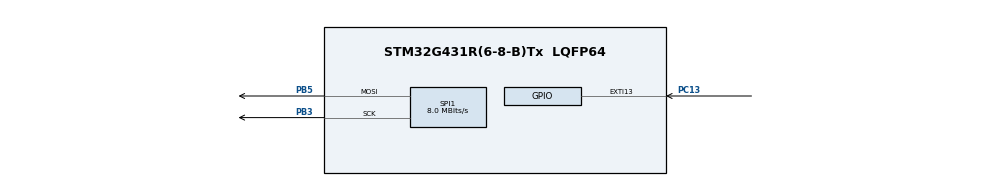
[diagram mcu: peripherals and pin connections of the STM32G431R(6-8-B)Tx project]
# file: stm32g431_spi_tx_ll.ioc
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Dma.Request0=SPI1_TX
Dma.SPI1_TX.0.Direction=DMA_MEMORY_TO_PERIPH
Dma.SPI1_TX.0.EventEnable=DISABLE
Dma.SPI1_TX.0.Instance=DMA1_Channel2
Dma.SPI1_TX.0.MemDataAlignment=DMA_MDATAALIGN_HALFWORD
Dma.SPI1_TX.0.MemInc=DMA_MINC_ENABLE
Dma.SPI1_TX.0.Mode=DMA_NORMAL
Dma.SPI1_TX.0.PeriphDataAlignment=DMA_PDATAALIGN_HALFWORD
Dma.SPI1_TX.0.PeriphInc=DMA_PINC_DISABLE
Dma.SPI1_TX.0.Polarity=HAL_DMAMUX_REQ_GEN_RISING
Dma.SPI1_TX.0.Priority=DMA_PRIORITY_LOW
Dma.SPI1_TX.0.RequestNumber=1
Dma.SPI1_TX.0.SignalID=NONE
Dma.SPI1_TX.0.SyncEnable=DISABLE
Dma.SPI1_TX.0.SyncPolarity=HAL_DMAMUX_SYNC_NO_EVENT
Dma.SPI1_TX.0.SyncRequestNumber=1
Dma.SPI1_TX.0.SyncSignalID=NONE
Mcu.Family=STM32G4
Mcu.Name=STM32G431R(6-8-B)Tx
Mcu.Package=LQFP64
NVIC.DMA1_Channel2_IRQn=true\:0\:0\:false\:false\:true\:false\:true\:true
NVIC.EXTI15_10_IRQn=true\:0\:0\:false\:false\:true\:true\:true\:true
NVIC.PriorityGroup=NVIC_PRIORITYGROUP_4
PB3.Mode=TX_Only_Simplex_Unidirect_Master
PB3.Signal=SPI1_SCK
PB5.Mode=TX_Only_Simplex_Unidirect_Master
PB5.Signal=SPI1_MOSI
PC13.Signal=GPXTI13
ProjectManager.HeapSize=0x200
ProjectManager.StackSize=0x400
ProjectManager.TargetToolchain=STM32CubeIDE
RCC.AHBFreq_Value=16000000
RCC.APB1Freq_Value=16000000
RCC.APB1TimFreq_Value=16000000
RCC.APB2Freq_Value=16000000
RCC.APB2TimFreq_Value=16000000
RCC.CortexFreq_Value=16000000
RCC.EXTERNAL_CLOCK_VALUE=12288000
RCC.HCLKFreq_Value=16000000
RCC.HSE_VALUE=8000000
RCC.HSI48_VALUE=48000000
RCC.HSI_VALUE=16000000
RCC.LSE_VALUE=32768
RCC.SYSCLKFreq_VALUE=16000000
RCC.USBFreq_Value=64000000
RCC.VCOOutputFreq_Value=128000000
SPI1.CLKPhase=SPI_PHASE_2EDGE
SPI1.CLKPolarity=SPI_POLARITY_HIGH
SPI1.CalculateBaudRate=8.0 MBits/s
SPI1.DataSize=SPI_DATASIZE_16BIT
SPI1.Direction=SPI_DIRECTION_2LINES
SPI1.Mode=SPI_MODE_MASTER
SPI1.VirtualType=VM_MASTER
VP_SYS_VS_DBSignals.Mode=DisableDeadBatterySignals
board=custom

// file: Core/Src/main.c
/* USER CODE BEGIN Header */
/**
  ******************************************************************************
  * @file           : main.c
  * @brief          : Main program body
  ******************************************************************************
  * @attention
  *
  * Copyright (c) 2023 STMicroelectronics.
  * All rights reserved.
  *
  * This software is licensed under terms that can be found in the LICENSE file
  * in the root directory of this software component.
  * If no LICENSE file comes with this software, it is provided AS-IS.
  *
  ******************************************************************************
  */
/* USER CODE END Header */
#include "main.h"

void SystemClock_Config(void);
static void MX_GPIO_Init(void);
static void MX_DMA_Init(void);
static void MX_SPI1_Init(void);

/* USER CODE BEGIN 0 */
uint8_t aTxBuffer[] = {0xAA, 0xAA};
uint8_t ubNbDataToTransmit = 1;
/* USER CODE END 0 */

int main(void)
{

  /* MCU Configuration--------------------------------------------------------*/

  /* Reset of all peripherals, Initializes the Flash interface and the Systick. */
  LL_APB2_GRP1_EnableClock(LL_APB2_GRP1_PERIPH_SYSCFG);
  LL_APB1_GRP1_EnableClock(LL_APB1_GRP1_PERIPH_PWR);

  /* System interrupt init*/
  NVIC_SetPriorityGrouping(NVIC_PRIORITYGROUP_4);

  /* SysTick_IRQn interrupt configuration */
  NVIC_SetPriority(SysTick_IRQn, NVIC_EncodePriority(NVIC_GetPriorityGrouping(),15, 0));

  /** Disable the internal Pull-Up in Dead Battery pins of UCPD peripheral
  */
  LL_PWR_DisableUCPDDeadBattery();

  /* Configure the system clock */
  SystemClock_Config();

  /* Initialize all configured peripherals */
  MX_GPIO_Init();
  MX_DMA_Init();
  MX_SPI1_Init();
  /* USER CODE BEGIN 2 */
  LL_SPI_SetRxFIFOThreshold(SPI1, LL_SPI_RX_FIFO_TH_HALF);
  LL_DMA_ConfigAddresses(DMA1,
                         LL_DMA_CHANNEL_2,
                         (uint32_t)aTxBuffer,
                         LL_SPI_DMA_GetRegAddr(SPI1),
                         LL_DMA_GetDataTransferDirection(DMA1, LL_DMA_CHANNEL_2));

  LL_DMA_SetDataLength(DMA1, LL_DMA_CHANNEL_2, ubNbDataToTransmit);
  LL_DMA_SetPeriphRequest(DMA1, LL_DMA_CHANNEL_2, LL_DMAMUX_REQ_SPI1_TX);
  LL_DMA_EnableIT_TC(DMA1, LL_DMA_CHANNEL_2);
  LL_DMA_EnableIT_TE(DMA1, LL_DMA_CHANNEL_2);

  //LL_SPI_EnableIT_TXE(SPI1);
  //LL_DMA_EnableChannel(DMA1, LL_DMA_CHANNEL_2);
  //LL_SPI_EnableDMAReq_TX(SPI1);
  //LL_SPI_Enable(SPI1);

  /* USER CODE END 2 */

  /* Infinite loop */
  while (1)
  {

  }
}

void SystemClock_Config(void)
{
  LL_FLASH_SetLatency(LL_FLASH_LATENCY_0);
  while(LL_FLASH_GetLatency() != LL_FLASH_LATENCY_0)
  {
  }
  LL_PWR_SetRegulVoltageScaling(LL_PWR_REGU_VOLTAGE_SCALE1);
  LL_RCC_HSI_Enable();
   /* Wait till HSI is ready */
  while(LL_RCC_HSI_IsReady() != 1)
  {
  }

  LL_RCC_HSI_SetCalibTrimming(64);
  LL_RCC_SetSysClkSource(LL_RCC_SYS_CLKSOURCE_HSI);
   /* Wait till System clock is ready */
  while(LL_RCC_GetSysClkSource() != LL_RCC_SYS_CLKSOURCE_STATUS_HSI)
  {
  }

  /* Set AHB prescaler*/
  LL_RCC_SetAHBPrescaler(LL_RCC_SYSCLK_DIV_1);
  LL_RCC_SetAPB1Prescaler(LL_RCC_APB1_DIV_1);
  LL_RCC_SetAPB2Prescaler(LL_RCC_APB2_DIV_1);

  LL_Init1msTick(16000000);

  LL_SetSystemCoreClock(16000000);
}

static void MX_SPI1_Init(void)
{

  LL_SPI_InitTypeDef SPI_InitStruct = {0};

  LL_GPIO_InitTypeDef GPIO_InitStruct = {0};

  /* Peripheral clock enable */
  LL_APB2_GRP1_EnableClock(LL_APB2_GRP1_PERIPH_SPI1);

  LL_AHB2_GRP1_EnableClock(LL_AHB2_GRP1_PERIPH_GPIOB);
  /**SPI1 GPIO Configuration
  PB3   ------> SPI1_SCK
  PB5   ------> SPI1_MOSI
  */
  GPIO_InitStruct.Pin = LL_GPIO_PIN_3;
  GPIO_InitStruct.Mode = LL_GPIO_MODE_ALTERNATE;
  GPIO_InitStruct.Speed = LL_GPIO_SPEED_FREQ_LOW;
  GPIO_InitStruct.OutputType = LL_GPIO_OUTPUT_PUSHPULL;
  GPIO_InitStruct.Pull = LL_GPIO_PULL_NO;
  GPIO_InitStruct.Alternate = LL_GPIO_AF_5;
  LL_GPIO_Init(GPIOB, &GPIO_InitStruct);

  GPIO_InitStruct.Pin = LL_GPIO_PIN_5;
  GPIO_InitStruct.Mode = LL_GPIO_MODE_ALTERNATE;
  GPIO_InitStruct.Speed = LL_GPIO_SPEED_FREQ_LOW;
  GPIO_InitStruct.OutputType = LL_GPIO_OUTPUT_PUSHPULL;
  GPIO_InitStruct.Pull = LL_GPIO_PULL_NO;
  GPIO_InitStruct.Alternate = LL_GPIO_AF_5;
  LL_GPIO_Init(GPIOB, &GPIO_InitStruct);

  /* SPI1 DMA Init */

  /* SPI1_TX Init */
  LL_DMA_SetPeriphRequest(DMA1, LL_DMA_CHANNEL_2, LL_DMAMUX_REQ_SPI1_TX);

  LL_DMA_SetDataTransferDirection(DMA1, LL_DMA_CHANNEL_2, LL_DMA_DIRECTION_MEMORY_TO_PERIPH);

  LL_DMA_SetChannelPriorityLevel(DMA1, LL_DMA_CHANNEL_2, LL_DMA_PRIORITY_LOW);

  LL_DMA_SetMode(DMA1, LL_DMA_CHANNEL_2, LL_DMA_MODE_NORMAL);

  LL_DMA_SetPeriphIncMode(DMA1, LL_DMA_CHANNEL_2, LL_DMA_PERIPH_NOINCREMENT);

  LL_DMA_SetMemoryIncMode(DMA1, LL_DMA_CHANNEL_2, LL_DMA_MEMORY_INCREMENT);

  LL_DMA_SetPeriphSize(DMA1, LL_DMA_CHANNEL_2, LL_DMA_PDATAALIGN_HALFWORD);

  LL_DMA_SetMemorySize(DMA1, LL_DMA_CHANNEL_2, LL_DMA_MDATAALIGN_HALFWORD);

  /* SPI1 parameter configuration*/
  SPI_InitStruct.TransferDirection = LL_SPI_FULL_DUPLEX;
  SPI_InitStruct.Mode = LL_SPI_MODE_MASTER;
  SPI_InitStruct.DataWidth = LL_SPI_DATAWIDTH_16BIT;
  SPI_InitStruct.ClockPolarity = LL_SPI_POLARITY_HIGH;
  SPI_InitStruct.ClockPhase = LL_SPI_PHASE_2EDGE;
  SPI_InitStruct.NSS = LL_SPI_NSS_SOFT;
  SPI_InitStruct.BaudRate = LL_SPI_BAUDRATEPRESCALER_DIV2;
  SPI_InitStruct.BitOrder = LL_SPI_MSB_FIRST;
  SPI_InitStruct.CRCCalculation = LL_SPI_CRCCALCULATION_DISABLE;
  SPI_InitStruct.CRCPoly = 7;
  LL_SPI_Init(SPI1, &SPI_InitStruct);
  LL_SPI_SetStandard(SPI1, LL_SPI_PROTOCOL_MOTOROLA);
  LL_SPI_DisableNSSPulseMgt(SPI1);

}

static void MX_DMA_Init(void)
{

  /* Init with LL driver */
  /* DMA controller clock enable */
  LL_AHB1_GRP1_EnableClock(LL_AHB1_GRP1_PERIPH_DMAMUX1);
  LL_AHB1_GRP1_EnableClock(LL_AHB1_GRP1_PERIPH_DMA1);

  /* DMA interrupt init */
  /* DMA1_Channel2_IRQn interrupt configuration */
  NVIC_SetPriority(DMA1_Channel2_IRQn, NVIC_EncodePriority(NVIC_GetPriorityGrouping(),0, 0));
  NVIC_EnableIRQ(DMA1_Channel2_IRQn);

}

static void MX_GPIO_Init(void)
{
  LL_EXTI_InitTypeDef EXTI_InitStruct = {0};

  /* GPIO Ports Clock Enable */
  LL_AHB2_GRP1_EnableClock(LL_AHB2_GRP1_PERIPH_GPIOC);
  LL_AHB2_GRP1_EnableClock(LL_AHB2_GRP1_PERIPH_GPIOB);

  /**/
  LL_SYSCFG_SetEXTISource(LL_SYSCFG_EXTI_PORTC, LL_SYSCFG_EXTI_LINE13);

  /**/
  EXTI_InitStruct.Line_0_31 = LL_EXTI_LINE_13;
  EXTI_InitStruct.LineCommand = ENABLE;
  EXTI_InitStruct.Mode = LL_EXTI_MODE_IT;
  EXTI_InitStruct.Trigger = LL_EXTI_TRIGGER_RISING;
  LL_EXTI_Init(&EXTI_InitStruct);

  /**/
  LL_GPIO_SetPinPull(GPIOC, LL_GPIO_PIN_13, LL_GPIO_PULL_NO);

  /**/
  LL_GPIO_SetPinMode(GPIOC, LL_GPIO_PIN_13, LL_GPIO_MODE_INPUT);

  /* EXTI interrupt init*/
  NVIC_SetPriority(EXTI15_10_IRQn, NVIC_EncodePriority(NVIC_GetPriorityGrouping(),0, 0));
  NVIC_EnableIRQ(EXTI15_10_IRQn);

}

void Error_Handler(void)
{
  __disable_irq();
  while (1)
  {
  }
}
